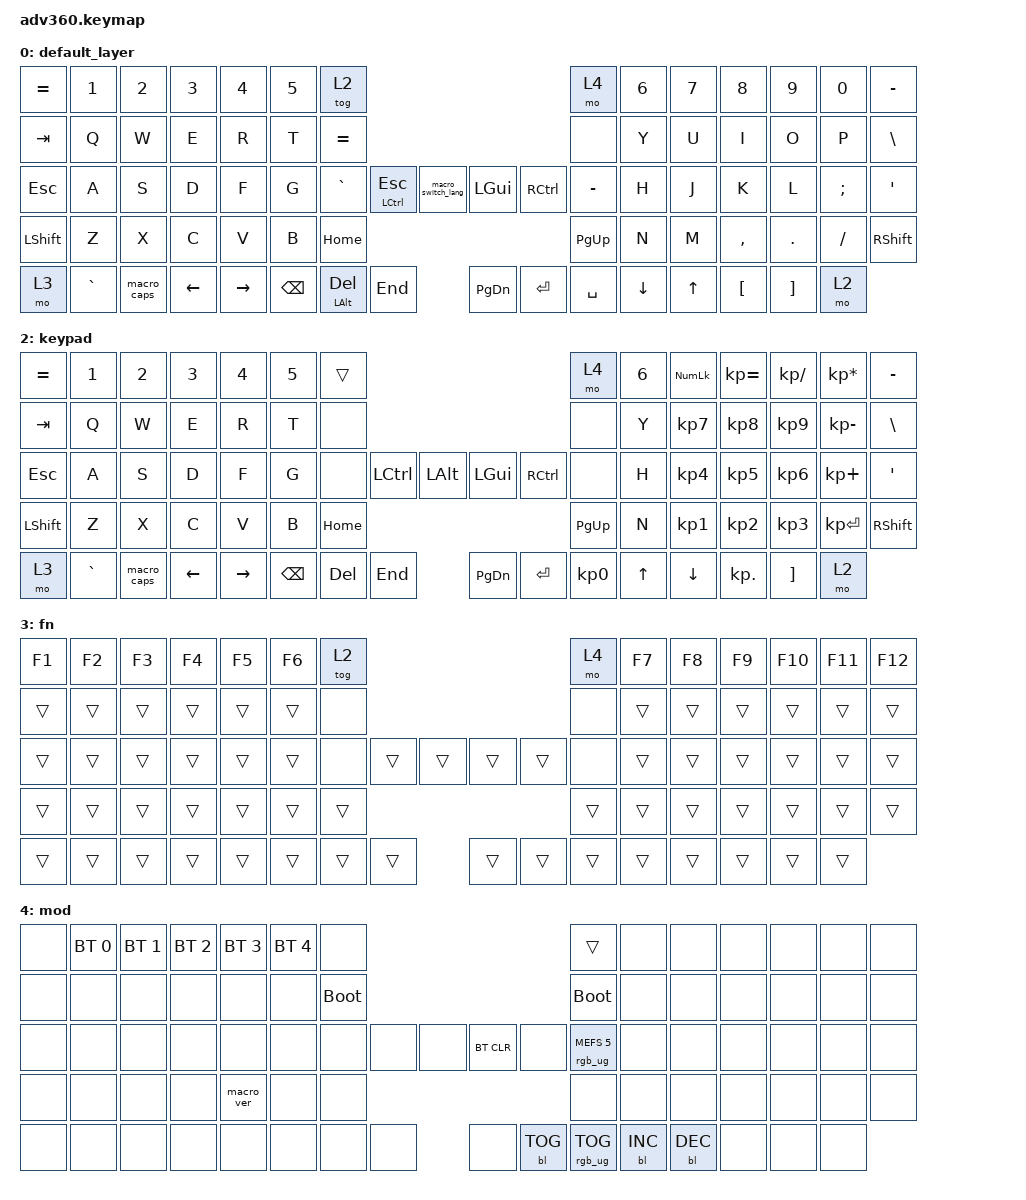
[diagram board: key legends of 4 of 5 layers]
#include <behaviors.dtsi>
#include <dt-bindings/zmk/keys.h>
#include <dt-bindings/zmk/bt.h>
#include <dt-bindings/zmk/rgb.h>
#include <dt-bindings/zmk/backlight.h>

#include "adv360_keypos.h"
#include "zmk_helper.h"

#include "general.h"

#include "homerow_mods.h"

#define DEFAULT_LAYER   0
#define CAPS_LAYER      1
#define KEYPAD_LAYER    2
#define FN_LAYER        3
#define MOD_LAYER       4

/ {
  behaviors {
    #include "macros.dtsi"
    #include "version.dtsi"
    #ifndef VERSION_MACRO
    macro_ver: macro_ver {
      compatible = "zmk,behavior-macro";
      label = "macro_version";
      #binding-cells = <0>;
      bindings = <&kp RET>;
    };
    #endif
  };

  macros {
    macro_switch_lang: macro_switch_lang {
      compatible = "zmk,behavior-macro";
      label = "SWITCH_LANGUAGE";
      #binding-cells = <0>;
      wait-ms = <40>;
      tap-ms = <40>;
      bindings = 
          <&macro_press   &kp LGUI>,
          <&macro_tap     &kp SPACE>,
          <&macro_release &kp LGUI>
      ;
    };
    
    macro_caps: macro_caps {
        compatible = "zmk,behavior-macro";
        label = "Caps Lock with Layer Switch";
        #binding-cells = <0>;
        bindings = <&kp CAPS &tog CAPS_LAYER>;
    };
  };

  keymap {
    compatible = "zmk,keymap";

    default_layer {
      bindings = <
        &kp EQUAL &kp N1    &kp N2   &kp N3   &kp N4     &kp N5 &tog 2                                                                  &mo 4     &kp N6  &kp N7    &kp N8    &kp N9   &kp N0   &kp MINUS
        &kp TAB   &kp Q     &kp W    &kp E    &kp R      &kp T  &kp EQUAL                                                               &none     &kp Y   &kp U     &kp I     &kp O    &kp P    &kp BSLH
        &kp ESC   &kp A     &kp S    &kp D    &kp F      &kp G  &kp GRAVE     &mt LCTRL ESC &macro_switch_lang &kp LGUI  &kp RCTRL      &kp MINUS &kp H   &kp J     &kp K     &kp L    &kp SEMI &kp SQT
        &kp LSHFT &kp Z     &kp X    &kp C    &kp V      &kp B                            &kp HOME &kp PG_UP                                      &kp N   &kp M     &kp COMMA &kp DOT  &kp FSLH &kp RSHFT
        &mo 3     &kp GRAVE &macro_caps &kp LEFT &kp RIGHT          &kp BSPC &mt LALT DEL  &kp END  &kp PG_DN &kp ENTER &kp SPACE                 &kp DOWN  &kp UP    &kp LBKT &kp RBKT &mo 2
      >;
    };
    caps_lock_layer {
      bindings = <
        &trans &trans &trans &trans &trans &trans &trans                                              &trans &trans &trans &trans &trans &trans &trans
        &trans &trans &trans &trans &trans &trans &trans                                              &trans &trans &trans &trans &trans &trans &trans
        &trans &trans &trans &trans &trans &trans &trans        &macro_caps &trans &trans             &trans &trans &trans &trans &trans &trans &trans
        &trans &trans &trans &trans &trans &trans                           &trans &trans                    &trans &trans &trans &trans &trans &trans
        &trans &trans &trans &trans &trans                    &trans &trans &trans &trans &trans &trans             &trans &trans &trans &trans &trans
      >;
    };
    keypad {
      bindings = < &kp EQUAL &kp N1 &kp N2 &kp N3 &kp N4 &kp N5 &trans                                                           &mo 4 &kp N6 &kp KP_NUM &kp KP_EQUAL &kp KP_DIVIDE &kp KP_MULTIPLY &kp MINUS
        &kp TAB   &kp Q     &kp W    &kp E    &kp R      &kp T  &none                                                            &none &kp Y  &kp KP_N7  &kp KP_N8    &kp KP_N9     &kp KP_MINUS    &kp BSLH
        &kp ESC   &kp A     &kp S    &kp D    &kp F      &kp G  &none           &kp LCTRL &kp LALT &kp LGUI  &kp RCTRL           &none &kp H  &kp KP_N4  &kp KP_N5    &kp KP_N6     &kp KP_PLUS     &kp SQT
        &kp LSHFT &kp Z     &kp X    &kp C    &kp V      &kp B                            &kp HOME &kp PG_UP                           &kp N  &kp KP_N1  &kp KP_N2    &kp KP_N3     &kp KP_ENTER    &kp RSHFT
        &mo 3     &kp GRAVE &macro_caps &kp LEFT &kp RIGHT                &kp BSPC &kp DEL   &kp END  &kp PG_DN &kp ENTER &kp KP_N0              &kp UP     &kp DOWN     &kp KP_DOT    &kp RBKT        &mo 2
      >;
    };
    fn {
      bindings = <
        &kp F1 &kp F2 &kp F3 &kp F4 &kp F5 &kp F6 &tog 2                                           &mo 4 &kp F7 &kp F8 &kp F9 &kp F10 &kp F11 &kp F12
        &trans &trans &trans &trans &trans &trans  &none                                           &none &trans &trans &trans &trans  &trans  &trans
        &trans &trans &trans &trans &trans &trans  &none        &trans &trans &trans &trans        &none &trans &trans &trans &trans  &trans  &trans
        &trans &trans &trans &trans &trans &trans                      &trans &trans                     &trans &trans &trans &trans  &trans  &trans
        &trans &trans &trans &trans &trans               &trans &trans &trans &trans &trans &trans              &trans &trans &trans  &trans  &trans
      >;
    };
    mod {
      bindings = <
        &none &bt BT_SEL 0 &bt BT_SEL 1 &bt BT_SEL 2 &bt BT_SEL 3 &bt BT_SEL 4 &none                                                                     &trans                 &none        &none        &none        &none &none &none
        &none &none        &none        &none        &none        &none        &bootloader                                                               &bootloader            &none        &none        &none        &none &none &none
        &none &none        &none        &none        &none        &none        &none                   &none &none &bt BT_CLR &none                      &rgb_ug RGB_MEFS_CMD 5 &none        &none        &none        &none &none &none
        &none &none        &none        &none        &macro_ver   &none                                      &none &none                                                        &none        &none        &none        &none &none &none
        &none &none        &none        &none        &none                                       &none &none &none &none      &bl BL_TOG &rgb_ug RGB_TOG                                     &bl BL_INC   &bl BL_DEC   &none &none &none
      >;
    };
  };
};
